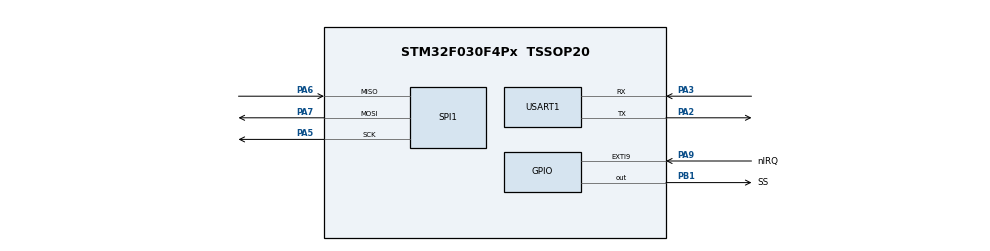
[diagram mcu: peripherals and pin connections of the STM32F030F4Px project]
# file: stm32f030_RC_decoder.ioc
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Dma.Request0=USART1_TX
Dma.USART1_TX.0.DMA_Remap=HAL_REMAPDMA_USART1_TX_DMA_CH4
Dma.USART1_TX.0.Direction=DMA_MEMORY_TO_PERIPH
Dma.USART1_TX.0.Instance=DMA1_Channel4
Dma.USART1_TX.0.MemDataAlignment=DMA_MDATAALIGN_BYTE
Dma.USART1_TX.0.MemInc=DMA_MINC_DISABLE
Dma.USART1_TX.0.Mode=DMA_CIRCULAR
Dma.USART1_TX.0.PeriphDataAlignment=DMA_PDATAALIGN_BYTE
Dma.USART1_TX.0.PeriphInc=DMA_PINC_DISABLE
Dma.USART1_TX.0.Priority=DMA_PRIORITY_MEDIUM
IWDG.Prescaler=IWDG_PRESCALER_32
IWDG.Reload=500
Mcu.Family=STM32F0
Mcu.Name=STM32F030F4Px
Mcu.Package=TSSOP20
NVIC.DMA1_Channel4_5_IRQn=true\:0\:0
NVIC.EXTI4_15_IRQn=true\:0\:0
NVIC.SPI1_IRQn=true\:0\:0
NVIC.USART1_IRQn=true\:0\:0
PA13.Mode=Serial-WireDebug
PA13.Signal=SYS_SWDIO
PA14.Mode=Serial-WireDebug
PA14.Signal=SYS_SWCLK
PA2.GPIO_Mode=GPIO_MODE_AF_PP
PA2.GPIO_PuPd=GPIO_NOPULL
PA2.GPIO_Speed=GPIO_SPEED_MEDIUM
PA2.Mode=Asynchronous
PA2.Signal=USART1_TX
PA3.GPIO_Mode=GPIO_MODE_AF_PP
PA3.GPIO_PuPd=GPIO_NOPULL
PA3.GPIO_Speed=GPIO_SPEED_MEDIUM
PA3.Mode=Asynchronous
PA3.Signal=USART1_RX
PA5.GPIO_Mode=GPIO_MODE_AF_PP
PA5.GPIO_PuPd=GPIO_NOPULL
PA5.GPIO_Speed=GPIO_SPEED_HIGH
PA5.Mode=Full_Duplex_Master
PA5.Signal=SPI1_SCK
PA6.GPIO_Mode=GPIO_MODE_AF_PP
PA6.GPIO_PuPd=GPIO_NOPULL
PA6.GPIO_Speed=GPIO_SPEED_HIGH
PA6.Mode=Full_Duplex_Master
PA6.Signal=SPI1_MISO
PA7.GPIO_Mode=GPIO_MODE_AF_PP
PA7.GPIO_PuPd=GPIO_NOPULL
PA7.GPIO_Speed=GPIO_SPEED_HIGH
PA7.Mode=Full_Duplex_Master
PA7.Signal=SPI1_MOSI
PA9.GPIO_Label=nIRQ
PA9.GPIO_ModeDefaultEXTI=GPIO_MODE_EVT_FALLING
PA9.GPIO_PuPd=GPIO_NOPULL
PA9.Signal=GPXTI9
PB1.GPIO_FMA9=__NULL
PB1.GPIO_Label=SS
PB1.GPIO_ModeDefaultOutputPP=GPIO_MODE_OUTPUT_PP
PB1.GPIO_PuPd=GPIO_PULLUP
PB1.GPIO_Speed=GPIO_SPEED_LOW
PB1.Signal=GPIO_Output
PF0-OSC_IN.Mode=HSE-External-Clock-Source
PF0-OSC_IN.Signal=RCC_OSC_IN
ProjectManager.TargetToolchain=MDK-ARM 4.73
RCC.HSE_VALUE=4000000
RCC.PLLMUL=RCC_PLL_MUL12
RCC.SYSCLKSource=RCC_SYSCLKSOURCE_PLLCLK
RCC.Usart1ClockSelection=RCC_USART1CLKSOURCE_SYSCLK
SPI1.BaudRatePrescaler-Full_Duplex_Master=SPI_BAUDRATEPRESCALER_8
SPI1.DataSize-Full_Duplex_Master=SPI_DATASIZE_16BIT
SPI1.Mode-Full_Duplex_Master=SPI_MODE_MASTER
USART1.BaudRate-Asynchronous=100000
USART1.MSBFirstParam-Asynchronous=UART_ADVFEATURE_MSBFIRST_ENABLE
USART1.Parity-Asynchronous=UART_PARITY_EVEN
USART1.StopBits-Asynchronous=UART_STOPBITS_2
USART1.WordLength-Asynchronous=UART_WORDLENGTH_9B
VP_IWDG_VS_IWDG.Mode=IWDG_Activate

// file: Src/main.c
/**
  ******************************************************************************
  * File Name          : main.c
  * Date               : 03/08/2014 21:24:35
  * Description        : Main program body
  ******************************************************************************
  *
  * COPYRIGHT(c) 2014 STMicroelectronics
  *
  * Redistribution and use in source and binary forms, with or without modification,
  * are permitted provided that the following conditions are met:
  *   1. Redistributions of source code must retain the above copyright notice,
  *      this list of conditions and the following disclaimer.
  *   2. Redistributions in binary form must reproduce the above copyright notice,
  *      this list of conditions and the following disclaimer in the documentation
  *      and/or other materials provided with the distribution.
  *   3. Neither the name of STMicroelectronics nor the names of its contributors
  *      may be used to endorse or promote products derived from this software
  *      without specific prior written permission.
  *
  * THIS SOFTWARE IS PROVIDED BY THE COPYRIGHT HOLDERS AND CONTRIBUTORS "AS IS"
  * AND ANY EXPRESS OR IMPLIED WARRANTIES, INCLUDING, BUT NOT LIMITED TO, THE
  * IMPLIED WARRANTIES OF MERCHANTABILITY AND FITNESS FOR A PARTICULAR PURPOSE ARE
  * DISCLAIMED. IN NO EVENT SHALL THE COPYRIGHT HOLDER OR CONTRIBUTORS BE LIABLE
  * FOR ANY DIRECT, INDIRECT, INCIDENTAL, SPECIAL, EXEMPLARY, OR CONSEQUENTIAL
  * DAMAGES (INCLUDING, BUT NOT LIMITED TO, PROCUREMENT OF SUBSTITUTE GOODS OR
  * SERVICES; LOSS OF USE, DATA, OR PROFITS; OR BUSINESS INTERRUPTION) HOWEVER
  * CAUSED AND ON ANY THEORY OF LIABILITY, WHETHER IN CONTRACT, STRICT LIABILITY,
  * OR TORT (INCLUDING NEGLIGENCE OR OTHERWISE) ARISING IN ANY WAY OUT OF THE USE
  * OF THIS SOFTWARE, EVEN IF ADVISED OF THE POSSIBILITY OF SUCH DAMAGE.
  *
  ******************************************************************************
  */

#include "stm32f0xx_hal.h"
#include "dma.h"
#include "iwdg.h"
#include "spi.h"
#include "usart.h"
#include "gpio.h"
#include "main.h"
//#include "rf22.h"
#include "fsm.h"
#include "fsm_rf22.h"
#include "fsm_uart.h"

void SystemClock_Config(void);

int main(void)
{

  /* MCU Configuration----------------------------------------------------------*/

  /* Reset of all peripherals, Initializes the Flash interface and the Systick. */
  HAL_Init();

  /* Configure the system clock */
  SystemClock_Config();

  /* System interrupt init*/
  HAL_NVIC_SetPriority(SysTick_IRQn, 0, 0);

	/* Configure Systick timer to interrupt every 1ms. Not needed calling SystemCoreClockUpdate(),
	because previously called HAL_RCC_ClockConfig()*/
	HAL_SYSTICK_Config(SystemCoreClock/1000);

  /* Initialize all configured peripherals */
  MX_GPIO_Init();
  MX_DMA_Init();
  MX_IWDG_Init();
  MX_SPI1_Init();
  MX_USART1_UART_Init();

  //timer_init();
	InitTimers();
	InitMessages();
	fsm_rf22_init();
	fsm_uart_init();
	fsm_init();

  /* USER CODE BEGIN 3 */
  /* Infinite loop */
  while (1)
  {
    ProcessTimers();
    // FSMs' processing here
    fsm_main();
		fsm_rf22();
		fsm_uart();
        /*if(GetTimer(HEAT_TIMER)>= (5*sec)) {
            Serial.println(GetTimer(HEAT_TIMER));
            ResetTimer(HEAT_TIMER);
            CMD_message=CMD_DS_INIT;
            SendMessageWParam(MSG_DS, &CMD_message);
        }*/
		// process messages
		ProcessMessages();
  }
  /* USER CODE END 3 */

}

/** System Clock Configuration
*/
void SystemClock_Config(void)
{

  RCC_ClkInitTypeDef RCC_ClkInitStruct;
  RCC_PeriphCLKInitTypeDef PeriphClkInit;
  RCC_OscInitTypeDef RCC_OscInitStruct;

  RCC_OscInitStruct.OscillatorType = RCC_OSCILLATORTYPE_HSI|RCC_OSCILLATORTYPE_LSI;
  RCC_OscInitStruct.HSIState = RCC_HSI_ON;
  RCC_OscInitStruct.HSICalibrationValue = 16;
  RCC_OscInitStruct.LSIState = RCC_LSI_ON;
  RCC_OscInitStruct.PLL.PLLState = RCC_PLL_ON;
  RCC_OscInitStruct.PLL.PLLSource = RCC_PLLSOURCE_HSI;
  RCC_OscInitStruct.PLL.PLLMUL = RCC_PLL_MUL12;
  RCC_OscInitStruct.PLL.PREDIV = RCC_PREDIV_DIV1;
  HAL_RCC_OscConfig(&RCC_OscInitStruct);

  RCC_ClkInitStruct.ClockType = RCC_CLOCKTYPE_SYSCLK;
  RCC_ClkInitStruct.SYSCLKSource = RCC_SYSCLKSOURCE_PLLCLK;
  RCC_ClkInitStruct.AHBCLKDivider = RCC_SYSCLK_DIV1;
  RCC_ClkInitStruct.APB1CLKDivider = RCC_HCLK_DIV1;
  HAL_RCC_ClockConfig(&RCC_ClkInitStruct, FLASH_LATENCY_0);

  PeriphClkInit.PeriphClockSelection = RCC_PERIPHCLK_USART1;
  PeriphClkInit.Usart1ClockSelection = RCC_USART1CLKSOURCE_SYSCLK;
  HAL_RCCEx_PeriphCLKConfig(&PeriphClkInit);

  __SYSCFG_CLK_ENABLE();

}

/************************ (C) COPYRIGHT STMicroelectronics *****END OF FILE****/
